# EOS-S3 register map
File version: 0.1
CPU: CM4 r0p1, selectable endian, MPU, FPU, 3 interrupt priority bits
Registers are 32-bit, read-write, reset 0x0 unless marked. A register's access mark holds for its fields unless they carry their own. Offsets are from the block's base; [hi:lo] are bit positions; {n}, {i} and the like mark numbered series; 'fields as' and 'values as' point back to an identical list.

## PMU — Power Management Unit
Base 0x40002000
0x00 MISC_POR_0 — On POR Reset Domain
  [0] M4_Rst_Release — RWHC: In AP mode, (SPIS_SS is High by default) ( In Wearable Mode, it has NO effect). The Hardware will clear this bit if `AP_Reboot_enable_N` is programmed and M4 is waking up from Mode 1 (SD) to ensure the M4 is kept on Reset once waking up.
    0=keep_on_reset (Keep M4 Core on Reset); 1=release_from_reset (Release M4 Core Reset)
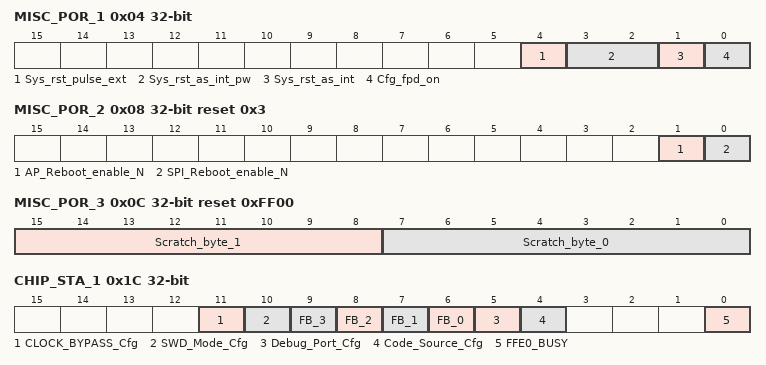
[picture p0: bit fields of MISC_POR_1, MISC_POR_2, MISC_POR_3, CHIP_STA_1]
0x04 MISC_POR_1 — On POR Reset Domain
  [4] Sys_rst_pulse_ext — If reset pin is still ketp low after the system reset INT is triggered, then the Chip will be reset if its pulse width is greater than configuration value
    0=after_4s (4S after INT trigger); 1=after_8s (8S after INT trigger)
  [3:2] Sys_rst_as_int_pw — If Sys_rst_as_int bit is programmed, then this system Reset INT will trigger if the reset pin is low and the pulse width greater than the configuration value.
    {v}=pulse_{v+1}S_{v+2}S (PWM must be {v+1}S ~ {v+2}S for Reset INT) (v=0..3)
  [1] Sys_rst_as_int — RWHC: Interrupt pin. This bit will be clear if System Reset Trigger when this bit is one
    0=sys_rst_as_chip_rst (Treat SYSTEM Reset as Chip Reset); 1=sys_rst_pin_as_exti (Reconfigure the SYSTEM Reset pin as the external interrupt pin)
  [0] Cfg_fpd_on — The FW need to program this bit if FW put the SPI flash to Power Down Mode. The CfgSM will wake up the Flash before reloading the boot code if this bit is 1. FW need to ensure this bit is clear after boot code reloading.
    1=wakeup_flash (The SPI is in Power Down Mode. If set, flash will be woken up)
0x08 MISC_POR_2 reset 0x3 — On POR Reset Domain
  [1] AP_Reboot_enable_N — If 1'b0, Need cfgSM to reload the code when M4 waking up from SD (Mode1) FW needs to clear this bit if needs code reloading from SPI flash once waking up from SD mdoe (MODE1). CfgSM will be kick off if code reloading from SPI flash needed. This is for code reloading ONLY.
    0=ap_code_reload (Need AP to reload the code when M4 waking up from SD (Mode1))
  [0] SPI_Reboot_enable_N — If 1'b0, Need cfgSM to reload the code when M4 waking up from SD (Mode1). FW needs to clear this bit if needs code reloading from SPI flash once waking up from SD mdoe (MODE1). CfgSM will be kick off if code reloading from SPI flash needed. This is for code reloading ONLY.
    0=spi_flash_code_reload (Need cfgSM to reload the code when M4 waking up from SD (Mode1))
0x0C MISC_POR_3 reset 0xFF00 — On POR Reset Domain
  [15:8] Scratch_byte_1 — Scratch Bytes, General Purpose Registers
  [7:0] Scratch_byte_0 — Scratch Bytes, General Purpose Registers
0x10 RST_CTRL_0 ro — Reserved
0x14 RST_CTRL_1 ro — Reserved
0x18 CHIP_STA_0 ro — Reserved
0x1C CHIP_STA_1 ro — Chip Status register
  [11] CLOCK_BYPASS_Cfg — This reflects the value of boot strap bit. Pad[9]
    1=external_clock_configured (The System Clock Source is from the I/O PAD instead of OSC if Debug_port_cfg is 1 as well.)
  [10] SWD_Mode_Cfg — This reflects the value of boot strap bit. Pad[20]
    1=if_swd_release_m4_on_rest (SWD debugger is attached. Release the M4 Core reset once System Reset released.)
  [n+6] FB_{n} (n=0..3) — FB Stasus Siganl {n} (Its definition is depending on the implementation of FB)
  [5] Debug_Port_Cfg — This reflects the value of boot strap bit. Pad[8]
    0=swd_pads_5_6 (SW_CLK @pad[5], SW_IO @pad[6]); 1=swd_pads_27_26 (SW_CLK @pad[27], SW_IO @pad[26])
  [4] Code_Source_Cfg — This reflects the value of boot strap bit. Pad[19]
    0=spi_flash (From SPI Flash, if SWD_Mode_Cfg is 1, CfgSM will not be kicked off.); 1=ap (From AP)
  [0] FFE0_BUSY — Indicates if FFE0 is busy
    0=not_busy (FFE0 is not busy); 1=busy (FFE0 is busy)
0x20 WIC_CTRL — Wake-up Interrupt Controller control register
  [0] WIC_Enable — RWHC: This bit will be clear once M4 is in Mode 1 (SD mode) by HW.
0x24 WIC_STATUS ro — Wake-up Interrupt Controller Status register
  [0] WIC_Ready — This bit is indicates that M4 Power Saving is enabled. This bit is based on the WIC/M4 interface signal.
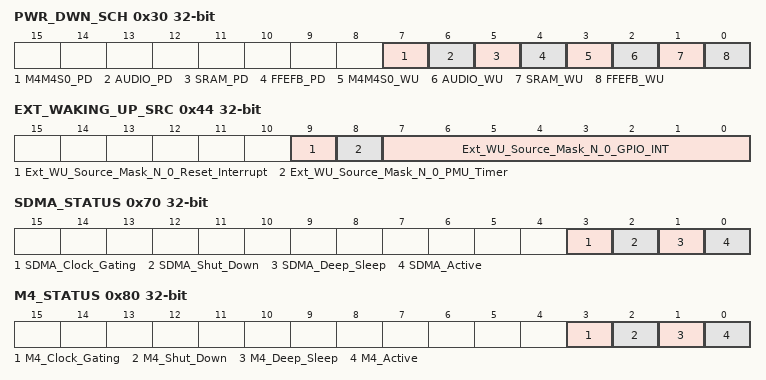
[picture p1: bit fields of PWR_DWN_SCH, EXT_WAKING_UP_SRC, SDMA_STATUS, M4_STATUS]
0x30 PWR_DWN_SCH — Power Down Scheme configuration
  [7] M4M4S0_PD — M4 and M4S0 simultaneous power-down behaviour
    0=secuential (Not defined. guess: First M4 then M4S0); 1=parallel (If M4 and M4S0 PD event happen at same time, then M4 and M4S0 will put into power saving mode at same time)
  [6] AUDIO_PD — AUDIO simultaneous power-down behaviour
    0=secuential (If more than one AUDIO Blocks (AD0 ~ AD5) PD event happen at same time, these Blocks will power down in the following priority. AD5->AD1->AD2->AD0->AD3->AD4. (AD5 has the highest priority and AD4 has the lowest priority)); 1=parallel (If more than one AUDIO Blocks (AD0 ~ AD5) PD event happen at same time, these AUDIO power domain will power down in parallel)
  [5] SRAM_PD — SRAM simultaneous power-down behaviour
    0=secuential (If more than one SRAM (M4S1 ~ M4S15) PD event happen at same time, these SRAMs will power down in the following priority. M4S1->M4S2->….->M4S14-> M4S15 (M4S1 has the highest priority and M4S15 has the lowest priority)); 1=parallel (If more than one SRAM (M4S1 ~ M4S15, NOT include M4S0) PD event happen at same time, these SRAMs will power down in parallel.)
  [4] FFEFB_PD — FFE and FB simultaneous power-down behaviour
    0=secuential (If FFE and FB PD event happen at same time, FB will power down first, then FFE.); 1=parallel (If FFE and FB PD event happen at same time, FFE and FB will power down in parallel)
  [3] M4M4S0_WU — M4 and M4S0 simultaneous wakeup-event behaviour
    0=secuential (Not defined. guess: First M4 then M4S0); 1=parallel (If M4 and M4S0 WU event happen at same time, then M4 and M4S0 will wake up at same time)
  [2] AUDIO_WU — Audio simultaneous wakeup-event behaviour
    0=secuential (If more than one AUDIO Blocks (AD0 ~ AD5) WU event happen at same time, these Blocks will wake up in the following priority. AD5->AD1->AD2->AD0->AD3->AD4. (AD5 has the highest priority and AD4 has the lowest priority)); 1=parallel (If more than one AUDIO Blocks (AD0 ~ AD5) WU event happen at same time, these AUDIO power domain will wake up in parallel)
  [1] SRAM_WU — SRAM simultaneous wakeup-event behaviour
    0=secuential (If more than one SRAM (M4S1 ~ M4S15) WU event happen at same time, these SRAMs will wake up in the following priority. M4S1->M4S2->….->M4S14-> M4S15 (M4S1 has the highest priority and M4S15 has the lowest priority)); 1=parallel (If more than one SRAM(M4S1 ~ M4S15, NOT include M4S0) WU event happen at same time, these SRAMs will wake up in parallel.)
  [0] FFEFB_WU — FFE and FB simultaneous wakeup-event behaviour
    0=secuential (If FFE and FB WU event happen at same time, FB will wake up first, then FFE.); 1=parallel (If FFE and FB WU event happen at same time, FFE and FB will wake up in parallel)
0x40 PWR_OFF_OSC — Control the power state of Oscillator once the M4 is in Power Saving Mode
  [0] Power_Off_OSC — 1'b1 : Turn Off OSC once the M4 is in Power Saving Mode
0x44 EXT_WAKING_UP_SRC — Configure the external wakeup event source. Turn on the OSC once PMUT is time out or GPIO INT is triggering.
  [9] Ext_WU_Source_Mask_N_0_Reset_Interrupt — Bit 9 : Reset Interrupt INT (Always Mask).
  [8] Ext_WU_Source_Mask_N_0_PMU_Timer — Bit 8 : PMU Timer
  [7:0] Ext_WU_Source_Mask_N_0_GPIO_INT — Bit 7:0 GPIO/Sensor INT, level only, (Raw information from PAD direclty) (Turn on OSC)
0x70 SDMA_STATUS ro
  [3] SDMA_Clock_Gating — Reserved
  [2] SDMA_Shut_Down — SDMA power domain is in Shut Down mode
  [1] SDMA_Deep_Sleep — SDMA power domain is in Deep Sleep Mode
  [0] SDMA_Active — SDMA power domain is active
0x74 SDMA_POWER_MODE_CFG — Register for SDMA Power Mode configuration
  [1:0] SDMA_Power_Mode_Cfg — FW need to configure the registers before kicking off the power down event.
    1=retention_mode; 2=shut_down_mode
0x78 SDMA_PD_SRC_MASK_N — Register for controlling if power down event will be masked
  [0] SDMA_PD_EVENT — 1'b0 : SDMA HW Power Down Event will be masked.
    0=mask (SDMA HW Power Down Event will be masked.); 1=Undefined Behaviour. Probably unmasks the Power Down event.
0x7C SDMA_WU_SRC_MASK_N ro — Reserved
0x80 M4_STATUS ro — Status of the M4 Power Domain
  [3] M4_Clock_Gating — Reserved
  [2] M4_Shut_Down — M4 Power Domain is in Shut Down mode
  [1] M4_Deep_Sleep — Reserved
  [0] M4_Active — M4 Power Domain is active
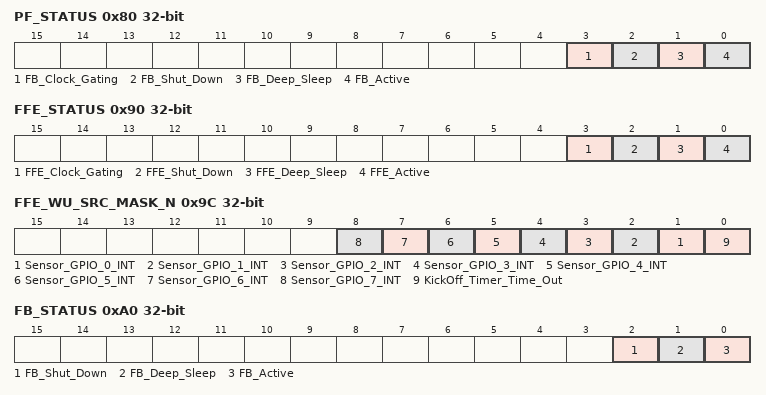
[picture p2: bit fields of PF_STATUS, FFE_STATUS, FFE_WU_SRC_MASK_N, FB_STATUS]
0x80 PF_STATUS ro — PF SRAM Power Domain status
  [3] FB_Clock_Gating — Reserved
  [2] FB_Shut_Down — PF SRAM Fabric Power domain is in mode
  [1] FB_Deep_Sleep — PF SRAM Fabric Power domain is in mode
  [0] FB_Active — PF SRAM Power domain is active
0x84 M4_PWR_MODE_CFG — Configuration for the M4 power domain
  [1:0] M4_Power_Mode_Cfg — FW need to configure the registers before clocking off the power down event
    2=shut_down_mode (Configure power down event for shut down mode)
0x88 M4_PD_SRC_MASKk_N ro — Reserved
0x8C M4_WU ro — Reserved
0x90 FFE_STATUS ro — Status of the Flexible Fusion Engine
  [3] FFE_Clock_Gating — Power Domain is alive, Onlt related clock is gated off -- This mode is for debugging only
  [2] FFE_Shut_Down — FFE Power Domain is in Shut_Down mode
  [1] FFE_Deep_Sleep — FFE Power Domain is in Deep Sleep mode
  [0] FFE_Active — FFE Power Domain is active
0x94 FFE_PWR_MODE_CFG — Power Mode configuration for the Flexible Fusion Engine Power Domain
  [1:0] FFE_Power_Mode_Cfg — FW need to configure the registers before kicking off the power down event.
    1=deep_sleep_mode (Configure power down event for deep sleep mode); 2=shut_down_mode (Configure power down event for shut down mode)
0x98 FFE_PD_SRC_MASK_N — Control masking of busy signal. The falling edge of any of the above signals (non-mask) will put the FFE into Power saving mode base on the Power Mode Cfg. Note: These signals used to indicate the BUSY status, so they must be level signals.
  [0] FFE_PD_Event_Mask — FFEs Busy Signal (FFE 0, SM 0 and SM1 Busy Signals ) Mask_N
    0=Masks the busy signal sources; 1=unmask (Will unmask the busy signal sources)
0x9C FFE_WU_SRC_MASK_N — Control the masking of the Flexible Fusion Engine wake-up event triggers
  [all] fields
    0=Mask the interrupt as a wake-up event source; 1=Unmask the interrupt as a wake-up event source
  [n+1] Sensor_GPIO_{n}_INT (n=0..7) — If unmasked, GPIO{n} interrupt will wake up FFE.
  [0] KickOff_Timer_Time_Out — If unmasked, kick off timer time-out event will wake up FFE.
0xA0 FB_STATUS ro — FPGA Fabric Power domain status
  [2] FB_Shut_Down — FPGA Fabric Power domain is in mode
  [1] FB_Deep_Sleep — FPGA Fabric Power domain is in mode
  [0] FB_Active — FPGA Fabric Power domain is active
0xA4 FB_PWR_MODE_CFG — Power mode configuration for the FPGA Fabric Power domain
  [1:0] FB_Power_Mode_Cfg — FW need to configure the registers before kicking off the power down event.
    values as FFE_PWR_MODE_CFG.FFE_Power_Mode_Cfg
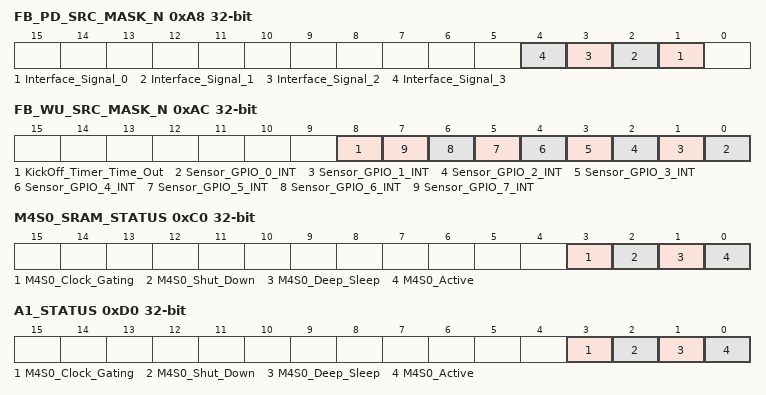
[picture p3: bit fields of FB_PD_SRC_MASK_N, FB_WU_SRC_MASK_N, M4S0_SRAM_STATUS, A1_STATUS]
0xA8 FB_PD_SRC_MASK_N — Control masking of power down event signals for the FPGA Fabric power domain. The falling edge of any of the listed signals (non-mask) will put the FB into Power saving mode base on the Power Mode Cfg. Note: These signals used to indicate the BUSY status, so they must be level signals.
  [all] fields
    0=Mask the signal as a power-down event source; 1=Unmask the signal as a power-down event source
  [n+1] Interface_Signal_{n} (n=0..3) — Control the mask for the Interface Signal {n}
0xAC FB_WU_SRC_MASK_N — Control the masking of the FPGA FAbric wake-up event triggers
  [all] fields
    values as the fields of FFE_WU_SRC_MASK_N
  [8] KickOff_Timer_Time_Out — If unmasked, kick off timer time-out event will wake up FB.
  [n] Sensor_GPIO_{n}_INT (n=0..7) — If unmasked, GPIO{n} interrupt will wake up FB.
0xB4 PF_PWR_MODE_CFG — Power mode configuration for the PF SRAM Power domain
  [1:0] PF_Power_Mode_Cfg — DW need to configure the registers before kicking off the power down event
    values as FFE_PWR_MODE_CFG.FFE_Power_Mode_Cfg
0xB8 PF_PD_SRC_MASK_N ro — Reserved
0xBC PF_WU_SRC_MASK_N ro — Reserved
0xC0 M4S0_SRAM_STATUS ro — M4S0 SRAM Power Domain status
  [3] M4S0_Clock_Gating — Reserved
  [2] M4S0_Shut_Down — PF SRAM Fabric Power domain is in mode.
  [1] M4S0_Deep_Sleep — Reserved. Deep Sleep not supported for this power domain.
  [0] M4S0_Active — PF SRAM Power domain is active.
0xC4 M4S0_PWR_MODE_CFG — Power mode configuration for the M4S0 SRAM power domain
  [1:0] M4S0_Power_Mode_Cfg — FW need to configure the registers before kicking off the power down event
    values as M4_PWR_MODE_CFG.M4_Power_Mode_Cfg
0xC8 M4S0_PD_SRC_MASK_N — Control masking of power-down event triggers for the M4S0 SRAM domain
  [0] M4S0_PD_Event_Mask — If not mask, The M4S0 power domain will put into Power Saving Mode base on Power_Mode_cfg once M4 is entering Shut Down mode and M4S0 power domain is NOT in power saving mode.
    0=mask (M4S0 SRAM Power Down Event will be masked.); 1=Undefined Behaviour. Probably unmasks the Power Down event.
0xCC M4S0_WU_SRC_MASK_N — Control masking of wake-up event triggers for the M4S0 SRAM domain
  [0] M4S0_PD_Event_Mask — If not mask, The M4S0 power domain will wake up once M4 is waking up from Power Saving and M4S0 power domain is NOT in active mode.
0xD0 A1_STATUS ro — Status of the A1 power domain
  [3] M4S0_Clock_Gating — Reserved
  [2] M4S0_Shut_Down — A1 Power domain is in mode.
  [1] M4S0_Deep_Sleep — A1 Power domain is in retention mode
  [0] M4S0_Active — A1 Power domain is active.
0xD4 A1_PWR_MODE_CFG — Power mode configuration for the A1 power domain
  [1:0] A1_Power_Mode_Cfg — FW need to configure the registers before kicking off the power down event
    1=retention_mode; 2=shut_down_mode
0xD8 A1_PD_SRC_MASK_N ro — Reserved
0xDC A1_WU_SRC_MASK_N — Control masking of wake-up event triggers for the A1 domain
  [0] A1_WU_EVENT_MASK_M — If Boot Code Reloading after M4 wake up is needed, this bit should be set to 1.
    0=Mask the M4 Wakeup event as the trigger for the A1 wake-up event; 1=Unmask M4 wake-up event as the trigger for the A1 wake-up
0xE0 MISC_STATUS ro — I2S Power info
  [4] I2S — Bit will be set if the I2S is powered on
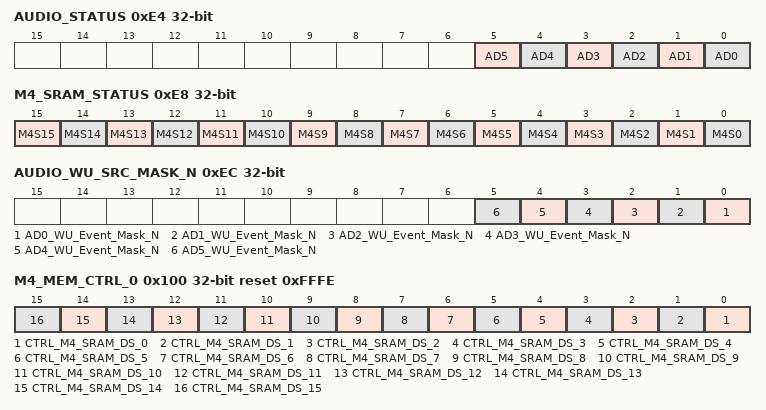
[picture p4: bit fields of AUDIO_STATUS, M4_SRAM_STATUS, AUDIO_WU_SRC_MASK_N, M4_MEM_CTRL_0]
0xE4 AUDIO_STATUS ro — Audio power domain status
  [n] AD{n} (n=1..5) — Bit is set if AD{n} power domain is on
  [0] AD0 — Bit is set if AD0 is on
0xE8 M4_SRAM_STATUS ro — M4 SRAM Power domain status
  [n] M4S{n} (n=1..15) — Bit is set if M4S{n} SRAM power domain is on
  [0] M4S0 — Bit is set if M4S0 SRAM power domain is on. Same as M4S0_SRAM_STATUS[0:0]
0xEC AUDIO_WU_SRC_MASK_N — Control masking of wake-up event triggers for the Audio domains
  [all] fields
    0=Mask the external interrupts from pads 9 or 30 as wake-up event triggers; 1=Unmask the external interrupts from pads 9 or 30 as wake-up event triggers
  [n] AD{n}_WU_Event_Mask_N (n=0..5) — Allow external interrupt coming from pads 9 or 30 to serve as wake-up event trigger
0x100 M4_MEM_CTRL_0 reset 0xFFFE — Control DS pins for different SRAM instances on the M4 subsystem. For each instance: 1'b1 : Enable the Deep Sleep funciton of SRAM Macro, Memory content will be kept. While M4 access the memory in Deep Sleep mode, the HW will clear the corresponding bit.
  [all] fields
    0=disable_deep_sleep (Disable the Deep Sleep function of SRAM Macro, Memory content will be kept.); 1=enable_deep_sleep (Enable the Deep Sleep function of SRAM Macro, Memory content will be kept.)
  [n] CTRL_M4_SRAM_DS_{n} (n=0..15) — Control DS pin of 32KB SRAM Instance {n} on M4 subsystem
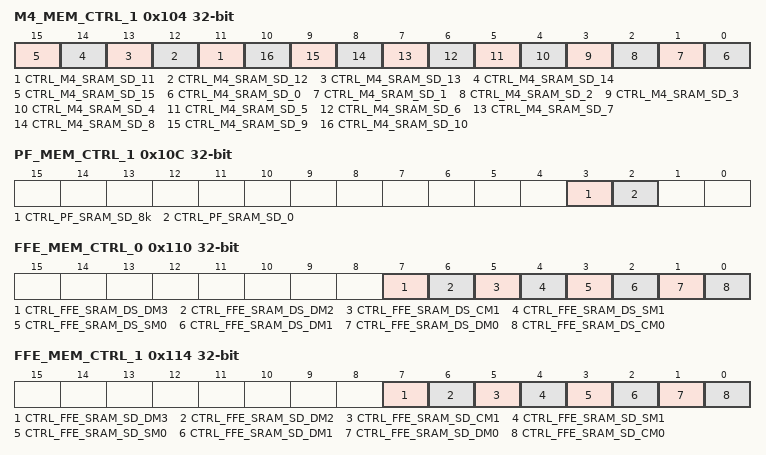
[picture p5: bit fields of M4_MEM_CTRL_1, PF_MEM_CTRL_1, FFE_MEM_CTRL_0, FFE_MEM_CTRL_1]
0x104 M4_MEM_CTRL_1 — Control Shutdown pin for various instances of SRAM on the M4 subsystem. For each instance: 1'b1 : Enable the Shutdown funciton of SRAM Macro, Memory content will be lost. While M4 access the memory in Shutdown mode, the HW will clear the corresponding bit.
  [all] fields
    0=disable_shut_down (Disable the shut down function of SRAM Macro.); 1=enable_shut_down (Enable the shut down function of SRAM Macro, Memory content will be lost.)
  [n] CTRL_M4_SRAM_SD_{n} (n=11..15) — Control SD pin of 32KB SRAM Instance 10 on M4 subsystem
  [n] CTRL_M4_SRAM_SD_{n} (n=0..10) — Control SD pin of 32KB SRAM Instance {n} on M4 subsystem
0x108 PF_MEM_CTRL_0 ro — RESERVED
0x10C PF_MEM_CTRL_1 — Control Shut Down pin of various FIFOs intances in the PF subsystem. For each one: 1'b1 : Enable the Shut Down function of SRAM Macro, Memory content will be lost
  [3] CTRL_PF_SRAM_SD_8k — Control SD Pin of FIFO_8k instances on PF subsystem
    values as the fields of M4_MEM_CTRL_1
  [2] CTRL_PF_SRAM_SD_0 — Control SD Pin of FIFO_2 instances on PF subsystem
    values as the fields of M4_MEM_CTRL_1
0x110 FFE_MEM_CTRL_0 — Control the Deep Sleep pin of various elements in the Flexible Fusion Engine power domain. For each: 1'b1 : Enable the Deep Sleep function of SRAM Macro, Memory content will be kept.
  [all] fields
    values as the fields of M4_MEM_CTRL_0
  [7] CTRL_FFE_SRAM_DS_DM3 — Control DS pin of CM0 1Kx32
  [6] CTRL_FFE_SRAM_DS_DM2 — Control DS pin of CM0 1Kx32
  [5] CTRL_FFE_SRAM_DS_CM1 — Control DS pin of CM1 2Kx40
  [4] CTRL_FFE_SRAM_DS_SM1 — Control DS pin of SM1 0.5Kx18
  [3] CTRL_FFE_SRAM_DS_SM0 — Control DS pin of SM0 1Kx18
  [2] CTRL_FFE_SRAM_DS_DM1 — Control DS pin of DM1 1Kx32
  [1] CTRL_FFE_SRAM_DS_DM0 — Control DS pin of DM0 1Kx32
  [0] CTRL_FFE_SRAM_DS_CM0 — Control DS pin of CM0 8Kx40
0x114 FFE_MEM_CTRL_1 — Control the Shut Down pin of various elements in the Flexible Fusion Engine power domain. For each: 1'b1 : Enable the Deep Sleep function of SRAM Macro, Memory content will be kept.
  [all] fields
    values as the fields of M4_MEM_CTRL_1
  [7] CTRL_FFE_SRAM_SD_DM3 — Control SD pin of CM0 1Kx32
  [6] CTRL_FFE_SRAM_SD_DM2 — Control SD pin of CM0 1Kx32
  [5] CTRL_FFE_SRAM_SD_CM1 — Control SD pin of CM1 2Kx40
  [4] CTRL_FFE_SRAM_SD_SM1 — Control SD pin of SM1 0.5Kx18
  [3] CTRL_FFE_SRAM_SD_SM0 — Control SD pin of SM0 1Kx18
  [2] CTRL_FFE_SRAM_SD_DM1 — Control SD pin of DM1 1Kx32
  [1] CTRL_FFE_SRAM_SD_DM0 — Control SD pin of DM0 1Kx32
  [0] CTRL_FFE_SRAM_SD_CM0 — Control SD pin of CM0 8Kx40
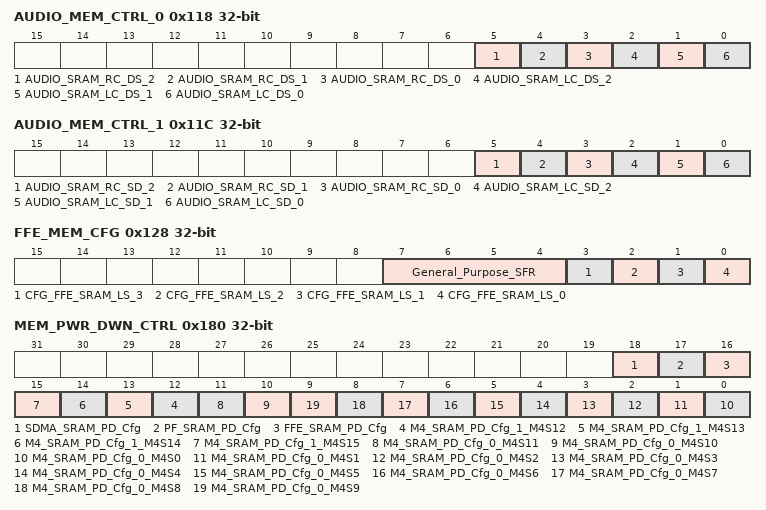
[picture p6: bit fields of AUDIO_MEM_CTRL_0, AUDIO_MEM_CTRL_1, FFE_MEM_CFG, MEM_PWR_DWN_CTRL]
0x118 AUDIO_MEM_CTRL_0 — Control the Deep Sleep pin of Audio channels. For each: 1'b1 : Enable the Deep Sleep function of SRAM Macro, Memory content will be kept.
  [all] fields
    values as the fields of M4_MEM_CTRL_0
  [5] AUDIO_SRAM_RC_DS_2 — Used to control DS pin of the Right Channel R2 256Kx15
  [4] AUDIO_SRAM_RC_DS_1 — Used to control DS pin of the Right Channel R1 128Kx32
  [3] AUDIO_SRAM_RC_DS_0 — Used to control DS pin of the Right Channel R0 2Kx32
  [2] AUDIO_SRAM_LC_DS_2 — Used to control DS pin of the Left Channel R2 256Kx15
  [1] AUDIO_SRAM_LC_DS_1 — Used to control DS pin of the Left Channel R1 128Kx32
  [0] AUDIO_SRAM_LC_DS_0 — Used to control DS pin of the Left Channel R0 2Kx32
0x11C AUDIO_MEM_CTRL_1 — Control the shut down pin of Audio channels. For each: 1'b1 : Enable the Deep Sleep function of SRAM Macro, Memory content will be kept.
  [all] fields
    values as the fields of M4_MEM_CTRL_1
  [5] AUDIO_SRAM_RC_SD_2 — Used to control SD pin of the Right Channel R2 256Kx15
  [4] AUDIO_SRAM_RC_SD_1 — Used to control SD pin of the Right Channel R1 128Kx32
  [3] AUDIO_SRAM_RC_SD_0 — Used to control SD pin of the Right Channel R0 2Kx32
  [2] AUDIO_SRAM_LC_SD_2 — Used to control SD pin of the Left Channel R2 256Kx15
  [1] AUDIO_SRAM_LC_SD_1 — Used to control SD pin of the Left Channel R1 128Kx32
  [0] AUDIO_SRAM_LC_SD_0 — Used to control SD pin of the Left Channel R0 2Kx32
0x120 M4_MEM_CFG ro — Reserved
0x124 PF_MEM_CFG ro — Reserved
0x128 FFE_MEM_CFG — Control Light Sleep pin of different FFE SRAM power domains
  [7:4] General_Purpose_SFR — Reseverd.
  [3] CFG_FFE_SRAM_LS_3 — Control LS pin of SM1
    0=disable_light_sleep (Disable, never put SRAM into Light Sleep mode.); 1=enable_light_sleep (Enable, Allow the Hardware control Light Speed pin of SRAM macro directly.)
  [2] CFG_FFE_SRAM_LS_2 — Control LS pin of SM0
    values as CFG_FFE_SRAM_LS_3
  [1] CFG_FFE_SRAM_LS_1 — Control LS pin of DM
    values as CFG_FFE_SRAM_LS_3
  [0] CFG_FFE_SRAM_LS_0 — Control LS pin of CM
    values as CFG_FFE_SRAM_LS_3
0x12C AUDIO_MEM_CFG ro — Reserved
{0x130+4i} M4_MEM_CTRL_PWR_{i} ro (i=0..2) — Reserved
0x140 SDMA_MEM_CTRL_0 — Control the Deep Sleep function of SRAM Macro for the SDMA power domain
  [0] SDMA_SRAM_DS — Used to control the Deep Sleep function of SRAM Macro, Memory content will be kept.
    values as the fields of M4_MEM_CTRL_0
0x144 SDMA_MEM_CTRL_1 — Control the Shut Down function of SRAM Macro for the SDMA power domain
  [0] SDMA_SRAM_SD — Used to control the Shut Down function of SRAM Macro, Memory content will be lost
    values as the fields of M4_MEM_CTRL_1
0x180 MEM_PWR_DWN_CTRL (reset mask 0x3FFFF) — Memory Power Down Control
  [18] SDMA_SRAM_PD_Cfg — Set to assert the DS pin of the SRAM Macro inside SDMA power domain if SDMA power domain is in Deep Sleep or Shut Down Mode.
  [17] PF_SRAM_PD_Cfg — Set to assert the DS pin of the SRAM Macro inside PF power domain if PF power domain is in Deep Sleep
  [16] FFE_SRAM_PD_Cfg — Set to assert the DS pin of the SRAM Macro inside FFE power domain if FFE power domain is in Deep Sleep
  [n] M4_SRAM_PD_Cfg_1_M4S{n} ro (n=12..15) — Set to put M4S{n} to Deep Sleep mode if M4 is in Shut Down Mode
  [11] M4_SRAM_PD_Cfg_0_M4S11 — Set to put M4S11 to Deep Sleep mode if M4 is in Shut Down Mode
  [10] M4_SRAM_PD_Cfg_0_M4S10 — Set tout M4S10 to Deep Sleep mode if M4 is in Shut Down Mode
  [n] M4_SRAM_PD_Cfg_0_M4S{n} (n=0..9) — Set to put M4S{n} to Deep Sleep mode if M4 is in Shut Down Mode
0x184 PMU_TIMER_CFG_0 — Configuration for the PMU timer time-out period
  [9:0] PMU_Time_Out_period — PMU timer is 16 bits running at 32KHZ. Once PMU timer bit 15:6 match the value of this register, PMUT INT will trigger and Timer will stop. 0 is a reserved value, min must be load value is 1.
0x188 PMU_TIMER_CFG_1 — Control wether the PMU timer is enabled or disabled
  [0] PMU_Timer_Enable — Set to enable PMU timer. Once disable, the PMU timer will be reset to all 0. FW need to disable the PMU timer once PMUT INT trigger. Please Note: It may take Up to 64uS to disable the time since this enable signal needs to sync to 32KHz clock domain from C10/C01 clock domain
0x18C PDWU_Timer_CFG — Control the delay for power-on after wake-up event. Applies to all power domains
  [2:0] PDWU_Timer_period — This is to define the additional IDLE cycles after Power Gating cell is off (Power is ON). This configuration applied to all power domain. Waits for reg value + 1 cycles, i.e. 0 - 1 cycle, 2 - 3 cycles, etc.
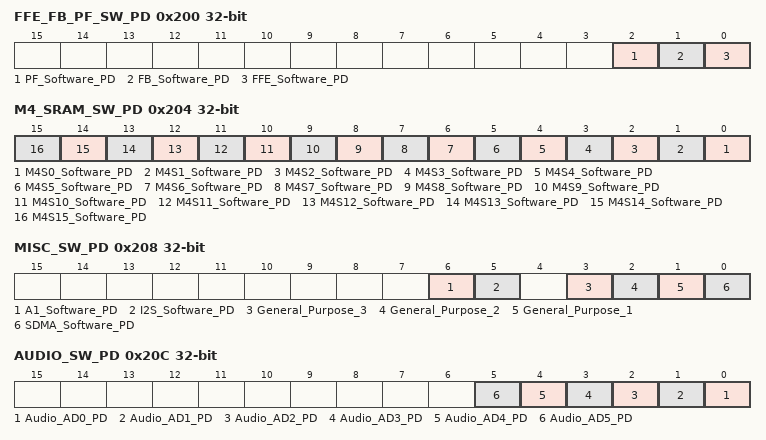
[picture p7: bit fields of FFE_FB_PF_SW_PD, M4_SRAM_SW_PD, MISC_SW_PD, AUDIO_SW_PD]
0x200 FFE_FB_PF_SW_PD — Registers for triggering power-down events in the FFE, FB and PF power domains.
  [all] fields
    1=power_down (Put the power domain to power saving mode according to configuration setting, HW will clear it once power down sequence is finished.)
  [2] PF_Software_PD — Set to trigger a power down event. Bit is cleared after power down sequence finishes
  [1] FB_Software_PD — Set to trigger a power down event. Bit is cleared after power down sequence finishes
  [0] FFE_Software_PD — Set to trigger a power down event. Bit is cleared after power down sequence finishes
0x204 M4_SRAM_SW_PD — Register for triggering power-down events in M4 SRAM power domains. (RWHC)
  [all] fields
    values as the fields of FFE_FB_PF_SW_PD
  [n] M4S{n}_Software_PD (n=0..15) — Set to trigger a power down event. Bit is cleared after power down sequence finishes
0x208 MISC_SW_PD (reset mask 0x3F) — Register for triggering power down events in MISC power domains + some general purpose SFR's (RWHC)
  [6] A1_Software_PD — Reserved for Future Use -- Power Domain. Set to put the power domain to power saving mode according to configuration setting, HW will clear it once power down sequence is finished.
    values as the fields of FFE_FB_PF_SW_PD
  [5] I2S_Software_PD — Reserved for Future Use -- Power Domain. Set to put the power domain to power saving mode according to configuration setting, HW will clear it once power down sequence is finished.
    values as the fields of FFE_FB_PF_SW_PD
  [3] General_Purpose_3 — General purpose SFR
  [2] General_Purpose_2 — General purpose SFR
  [1] General_Purpose_1 — General purpose SFR
  [0] SDMA_Software_PD — System DMA Power Domain. Set to put the power domain to power saving mode according to configuration setting, HW will clear it once power down sequence is finished.
    values as the fields of FFE_FB_PF_SW_PD
0x20C AUDIO_SW_PD reset not defined — Register for triggering power-down events in Audio power domains. (RWHC)
  [all] fields
    1=power_down (Put the power domain to shut down, HW will clear it once power down sequence is finished.)
  [n] Audio_AD{n}_PD (n=0..5) — Set to trigger a power down event. Bit will be cleared once power down sequence is finished
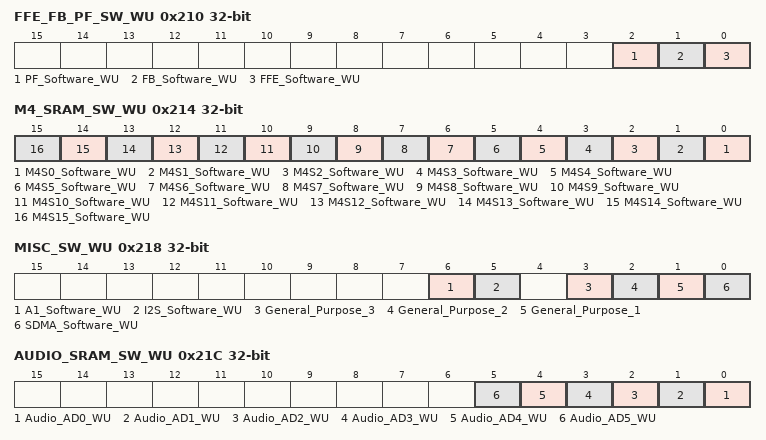
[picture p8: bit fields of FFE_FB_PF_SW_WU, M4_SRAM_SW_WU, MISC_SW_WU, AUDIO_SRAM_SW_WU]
0x210 FFE_FB_PF_SW_WU — Registers for triggering wake-up events in the FFE, FB and PF power domains.
  [all] fields
    1=wake up power domain, HW will clear it once power up sequence is finished
  [2] PF_Software_WU — Set to trigger a wake up event. Bit is cleared after wake up sequence finishes
  [1] FB_Software_WU — Set to trigger a wake up event. Bit is cleared after wake up sequence finishes
  [0] FFE_Software_WU — Set to trigger a wake up event. Bit is cleared after wake up sequence finishes
0x214 M4_SRAM_SW_WU — Register for triggering wake-up events in M4 SRAM power domains. (RWHC)
  [all] fields
    values as the fields of FFE_FB_PF_SW_WU
  [n] M4S{n}_Software_WU (n=0..15) — Set to trigger a wake up event. Bit is cleared after wake up sequence finishes
0x218 MISC_SW_WU (reset mask 0x3F) — Register for triggering wake up events in MISC power domains + some general purpose SFR's (RWHC)
  [6] A1_Software_WU — Reserved Logic Power Domain. Set to wake up power domain, HW will clear it once power up sequence is finished.
    values as the fields of FFE_FB_PF_SW_WU
  [5] I2S_Software_WU — Reserved Logic Power Domain. Set to wake up power domain, HW will clear it once power up sequence is finished.
    values as the fields of FFE_FB_PF_SW_WU
  [3] General_Purpose_3 — General purpose SFR
  [2] General_Purpose_2 — General purpose SFR
  [1] General_Purpose_1 — General purpose SFR
  [0] SDMA_Software_WU — SDMA Power Domain. Set to wake up power domain, HW will clear it once power up sequence is finished.
    values as the fields of FFE_FB_PF_SW_WU
0x21C AUDIO_SRAM_SW_WU reset not defined — Register for triggering wake-up events in Audio power domains. (RWHC)
  [all] fields
    values as the fields of FFE_FB_PF_SW_WU
  [n] Audio_AD{n}_WU (n=0..5) — Set to trigger a wake up event. Bit will be cleared once wake up sequence is finished
0x220 PMU_STM_PRIORITY — Power Management Unit Software Test Mode priority control
  [0] PMU_STM_PRIORITY — Controls how PMU STM and M4/FFE STM will be arbitrated.
    0=simultaneous (Audio/SRAM PMU STM (State Machine) and M4/FFE PMU STM could run at same time.); 1=round_robin (Audio/SRAM PMU STM and M4/FFE PMU STM will be arbitrate in Round Robin Scheme)
0x230 M4SRAM_SSW_LPMF — Control for M4SRAM power domain light sleep mode
  [15:0] M4SRAM_LPMF — Enable or disable Light Sleep Mode. If M4 SRAM power is removing, the corresponding bit will be clear.
    1=enable_light_sleep (Enable M4 SRAM Light Sleep Mode.)
0x234 M4SRAM_SSW_LPMH_MASK_N — Control masking for the LPMH (Low Power Mode header - deep sleep circuit)
  [15:0] M4SRAM_LPMH_MASK_N — if M4 SRAM power is removing Or SRAM is auto waking up from Deep Sleep Mode, the corresponding bit will be clear.
    0=lpmh_de_assert (M4 SRAM's LPMH will be de-asserted); 1=let_m4_mem_ctrl_0_control (M4_MEM_CTRL_0 will control the corresponding M4 SRAM's LPMH)
0x3E8 FBVLPMinWidth (reset mask 0x1111111111) — Configuration for the amount of IDLE cycles before powering on the FB domain
  [9:0] FBVLPMinWidth — For FB, it required additional IDLE Cylcle from turning off power gates (Power is ON) to ready for normal operation. This is used to defined the # of the IDLE cycles (base on C01 Clock). According to FB spec, it will require 10uS. But for final spec, it should be from FB design team.
0x3EC APRebootStatus — Indicates if AP nees to reload the code to SRAM
  [0] APRebootStatus — Set to indicate the AP need to reload the code to SRAM HW set to 1 and FW can clear it. This is allowed FW@AP to read this status.
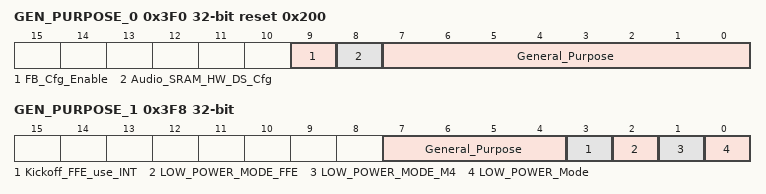
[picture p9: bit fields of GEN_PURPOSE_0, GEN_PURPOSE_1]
0x3F0 GEN_PURPOSE_0 reset 0x200 — Configure FB config enable and wether Audio SRAM can be put into Deep Sleep by the Audio hardware
  [9] FB_Cfg_Enable — Set to enable FB configuration. Hardware will set once entering FB shutdown mode
  [8] Audio_SRAM_HW_DS_Cfg — Set to allow audio HW to put the Audio SRAM into Deep Sleep mode. Please see Audio Spec for detail
  [7:0] General_Purpose — General purpose SFR
0x3F4 FB_ISOLATION — Control the FB Isolation
  [0] Enable_the_FB_Isolation — This bit will be set to 1 if FB is waking up from shut down mode. The FB interface wil be kept in isolation the domain, except for the FB configuration interface itself
0x3F8 GEN_PURPOSE_1 — Control for: Wether ext-interrupt can be used to wake up FFE, and clock switching for FFE/M4 power domains
  [7:4] General_Purpose — General purpose SFR
  [3] Kickoff_FFE_use_INT — Set to use external INT to wake up FFE.
  [2] LOW_POWER_MODE_FFE — Set to use FFE Power State to Turn on/off OSC and switching the Clock between OSC and RTC if Bit 0 is 1.
  [1] LOW_POWER_MODE_M4 — Set to use M4 Power State to Turn on/off OSC and switching the Clock between OSC and RTC if Bit 0 is 1
  [0] LOW_POWER_Mode — Set to enable the low power mdoe
